# SAMA7D65D2GN8 register map
Vendor: Microchip Technology; Series: SAMA7D6; File version: 0
Registers are 32-bit, read-write, reset 0x0 unless marked. A register's access mark holds for its fields unless they carry their own. Offsets are from the block's base; [hi:lo] are bit positions; {n}, {i} and the like mark numbered series; 'fields as' and 'values as' point back to an identical list.

## ASRC — Asynchronous Sample Rate Converter
Base 0xE2808000
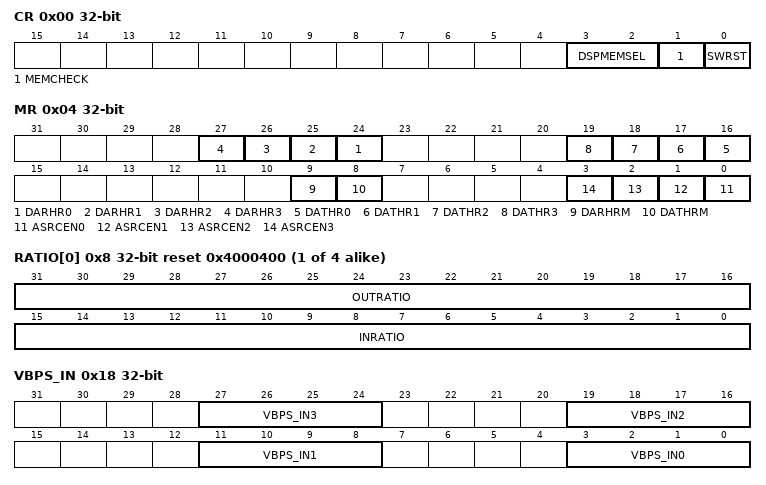
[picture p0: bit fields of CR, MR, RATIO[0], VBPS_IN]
0x00 CR wo — Control Register
  [3:2] DSPMEMSEL — DSP Memory Selection
    0=ALL_DSP_MEM (Memories of all DSPs are checked when MEMCHECK=1. When the flag ASRC_ESR.SRAMS=1, one error has been detected in one of the memories. To determine which DSP is affected, the memory check procedure must be restarted with DSPMEMSEL > 0. Note: When using only DSP0 or DSP1 or DSP3, it is possible to start the check procedure only for the selected DSP. The check of DSP2 memories requires several steps.); 1=DSP0_MEM (Only memories of DSP0 are checked when MEMCHECK=1. When the flag ASRC_ESR.SRAMS=1, one error has been detected in one of the memories associated to DSP0. The errors that may be located in other DSP memories does not impact the report on ASRC_ESR.SRAMS=1.); 2=DSP1_MEM (Only memories of DSP1 are checked when MEMCHECK=1. When the flag ASRC_ESR.SRAMS=1, one error has been detected in one of the memories associated to DSP1. The errors that may be located in other DSP memories does not impact the report on ASRC_ESR.SRAMS=1.); 3=DSP3_MEM (Only memories of DSP3 are checked when MEMCHECK=1. When the flag ASRC_ESR.SRAMS=1, one error has been detected in one of the memories associated to DSP3. The errors that may be located in other DSP memories does not impact the report on ASRC_ESR.SRAMS=1.)
  [1] MEMCHECK — Embedded Memory Check
    0=No effect; 1=Starts a memory check when all DSPs are disabled (ASRC_MR.ASRCENx=0). The end of the verification period is provided in ASRC_ISRx.EOMCP and the status is available in ASRC_ESR.ROMS/SRAMS at the end of the verification period. Clears the ASRC_ESR.ROMS/SRAMS flags.
  [0] SWRST — Software Reset
    0=No effect; 1=Resets the ASRC
0x04 MR — Mode Register
  [n+24] DARHR{n} (n=0..3) — Direct Access Receive Holding Register Destination
    0=DMA (The Receive Holding register is read by software or DMA. If DARHRM=1, the Receive Holding register is directly driving an audio peripheral. The Receive Holding register x loads the audio peripheral selected by ASRC_DAPSELR.OUT_CHx.); 1=DIRECT_ACCESS (The Receive Holding register is directly driving an audio peripheral. The Receive Holding register x loads the audio peripheral selected by ASRC_DAPSELR.OUT_CHx.)
  [n+16] DATHR{n} (n=0..3) — Direct Access Transmit Holding Register Source
    0=DMA (The Transmit Holding register is loaded by software or DMA. If DATHRM=1, the Transmit Holding register is directly loaded by an audio peripheral. The audio peripheral loading the Transmit Holding Register is selected by configuring ASRC_DAPSELR.IN_CHx.); 1=DIRECT_ACCESS (The Transmit Holding register is directly loaded by an audio peripheral. The audio peripheral loading the Transmit Holding Register is selected by configuring ASRC_DAPSELR.IN_CHx.)
  [9] DARHRM — Direct Access Receive Holding Registers Mode
    0=PER_RHR (The access mode for each receive channel (ASRC_RHRx) is defined by the bits DARHRx.); 1=ALL_RHR (All receive channels are directly driving audio peripherals. The DARHRx bits have no effect.)
  [8] DATHRM — Direct Access Transmit Holding Registers Mode
    0=PER_THR (The access mode for each transmit channel (ASRC_THRx) is defined by the bits DATHRx.); 1=ALL_THR (All transmit channels are directly loaded by audio peripherals. The DATHRx bits have no effect.)
  [n] ASRCEN{n} (n=0..3) — ASRC Stereo Channel {n} Enable
    0=DISABLE (DSPx is disabled.); 1=ENABLE (DSPx is enabled.)
{0x8+4i} RATIO[{i}] (i=0..3) reset 0x4000400 — Ratio Register of Stereo Channel x
  [31:16] OUTRATIO — Output Internal Sampling Rate Ratio
  [15:0] INRATIO — Input Internal Sampling Rate Ratio
0x18 VBPS_IN — Valid Bit Per Sample In Register
  [all] fields
    0=8_BIT (The 8 LSB of THR registers are left aligned on 24-bit data entered to the DSP. The bits [15:8] of the 24-bit data are driven by the 8 LSB of THR registers to increase the dynamic range of the data sent to DSP. The bits [7:0] are driven by 0s.); 1=16_BIT (The 16 LSB of THR registers are left aligned on 24-bit data entered to the DSP. The bits [7:0] of the 24-bit data are driven by the bits [15:8] of the THR registers to increase the dynamic range of the data sent to DSP.); 2=20_BIT (The 20 LSB of THR registers are left aligned on 24-bit data entered to the DSP. The bits [3:0] of the 24-bit data are driven by the bits [19:16] of the THR registers to increase the dynamic range of the data sent to DSP.); 3=24_BIT (The 24 LSB of THR registers are entered to the DSP.); 4=32_BIT (The 24 MSB of THR registers are entered to the DSP.); 5=10_BIT (The 10 LSB of THR registers are left aligned on 24-bit data entered to the DSP. The bits [13:4] of the 24-bit data are driven by the 10 LSB of THR registers to increase the dynamic range of the data sent to DSP. The bits [3:0] are driven by 0s.); 6=12_BIT (The 12 LSB of THR registers are left aligned on 24-bit data entered to the DSP. The bits [11:0] of the 24-bit data are driven by the bits [11:0] of the THR registers to increase the dynamic range of the data sent to DSP.); 7=14_BIT (The 14 LSB of THR registers are left aligned on 24-bit data entered to the DSP. The bits [9:0] of the 24-bit data are driven by the bits [13:4] of the THR registers to increase the dynamic range of the data sent to DSP.); 8=18_BIT (The 18 LSB of THR registers are left aligned on 24-bit data entered to the DSP. The bits [5:0] of the 24-bit data are driven by the bits [17:12] of the THR registers to increase the dynamic range of the data sent to DSP.)
  [8n+3:8n] VBPS_IN{n} (n=0..3) — Valid Bit Per Sample In of DSP {n}
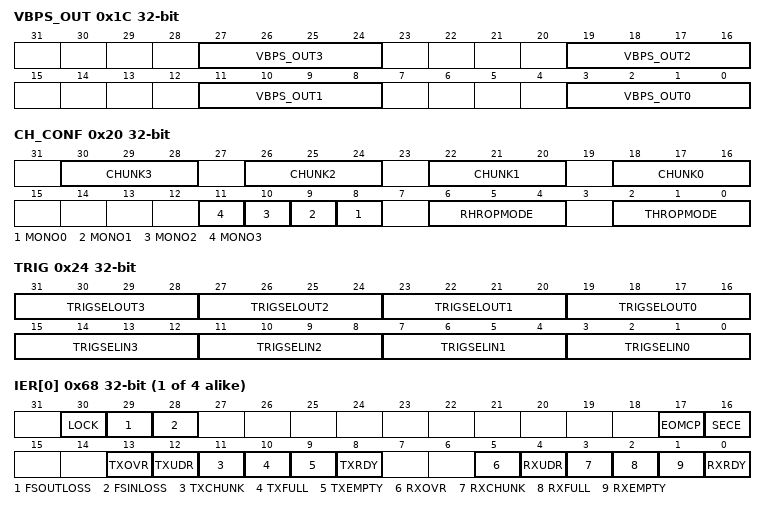
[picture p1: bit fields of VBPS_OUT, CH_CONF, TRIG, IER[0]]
0x1C VBPS_OUT — Valid Bit Per Sample Out Register
  [all] fields
    0=8_BIT (The 8 MSB of the 24-bit read from the DSP output are right-aligned on RHR.); 1=16_BIT (The 16 MSB of the 24-bit read from the DSP output are right-aligned on RHR.); 2=20_BIT (The 20 MSB of the 24-bit read from the DSP output are right-aligned on RHR.); 3=24_BIT (The 24 LSB of RHR registers are read from the 24-bit DSP output.); 4=32_BIT (The 24 MSB of RHR registers are the 24-bit output of the DSP. The 8 LSB of the RHR are driven by bits [22:15] of the DSP output.); 5=10_BIT (The 10 MSB of the 24-bit read from the DSP output are right-aligned on RHR.); 6=12_BIT (The 12 MSB of the 24-bit read from the DSP output are right-aligned on RHR.); 7=14_BIT (The 14 MSB of the 24-bit read from the DSP output are right-aligned on RHR.); 8=18_BIT (The 18 MSB of the 24-bit read from the DSP output are right-aligned on RHR.)
  [8n+3:8n] VBPS_OUT{n} (n=0..3) — Valid Bit Per Sample Out of DSP {n}
0x20 CH_CONF — Channel Configuration Register
  [4n+18:4n+16] CHUNK{n} (n=0..3) — DMA DSP {n} CHUNK Size
    0=1_DATA (The DMA chunk size must be configured to transfer 1 data for each rising edge of the trigger event.); 1=2_DATA (The DMA chunk size must be configured to transfer 2 data for each rising edge of the trigger event.); 2=4_DATA (The DMA chunk size must be configured to transfer 4 data for each rising edge of the trigger event.); 3=8_DATA (The DMA chunk size must be configured to transfer 8 data for each rising edge of the trigger event.); 4=16_DATA (The DMA chunk size must be configured to transfer 16 data for each rising edge of the trigger event.)
  [n+8] MONO{n} (n=0..3) — DSP {n} Mono Operating Mode
    0=DISABLED (DSP operates in Stereo mode.); 1=ENABLED (DSP operates in Mono mode.)
  [6:4] RHROPMODE — Receive Holding Registers Operating Mode
    0=RHRX_UPTO_2CH (The ASRC_RHRx can receive up to 2 audio streams (e.g. 1 stereo channel for each ASRC_RHR). Each ASRC_RHRx is routed on each Stereo DSP x.); 1=RHR0_UPTO_4CH (The ASRC_RHR0 can receive up to 4 audio streams (e.g. up to 2 stereo channels on ASRC_RHR0). The ARSC_RHR1 can receive up to 2 audio streams (e.g. 1 stereo channel on ASRC_RHR1). The ARSC_RHR2 can receive up to 2 audio streams (e.g. 1 stereo channel on ASRC_RHR2). ASRC_RHR3 must not be used.); 2=RHR01_UPTO_4CH (The ASRC_RHR0 can receive up to 4 audio streams (e.g. up to 2 stereo channels on ASRC_RHR0). The ASRC_RHR1 can receive up to 4 audio streams (e.g. up to 2 stereo channels on ASRC_RHR1). ASRC_RHR2 and ASRC_RHR3 must not be used.); 3=RHR0_UPTO_6CH (The ASRC_RHR0 can receive up to 6 audio streams (e.g. up to 3 stereo channels on ASRC_RHR0). The ARSC_RHR1 can receive up to 2 audio streams (e.g. 1 stereo channel on ASRC_RHR1) ASRC_RHR2 and ASRC_RHR3 must not be used.); 4=RHR0_UPTO_8CH (The ASRC_RHR0 can receive up to 8 audio streams (e.g. up to 4 stereo channels on ASRC_RHR0). ASRC_RHR1,ASRC_RHR2 and ASRC_RHR3 must not be used.)
  [2:0] THROPMODE — Transmit Holding Registers Operating Mode
    0=THRX_UPTO_2CH (The ASRC_THRx can receive up to 2 audio streams (e.g. 1 stereo channel for each ASRC_THR). Each ASRC_THRx is routed on each Stereo DSP x.); 1=THR0_UPTO_4CH (The ASRC_THR0 can receive up to 4 audio streams (e.g. up to 2 stereo channels on ASRC_THR0). The ARSC_THR1 can receive up to 2 audio streams (e.g. 1 stereo channel on ASRC_THR1). The ARSC_THR2 can receive up to 2 audio streams (e.g. 1 stereo channel on ASRC_THR2). ASRC_THR3 must not be used.); 2=THR01_UPTO_4CH (The ASRC_THR0 can receive up to 4 audio streams (e.g. up to 2 stereo channels on ASRC_THR0). The ASRC_THR1 can receive up to 4 audio streams (e.g. up to 2 stereo channels on ASRC_THR1). ASRC_THR2 and ASRC_THR3 must not be used.); 3=THR0_UPTO_6CH (The ASRC_THR0 can receive up to 6 audio streams (e.g. up to 3 stereo channels on ASRC_THR0). The ARSC_THR1 can receive up to 2 audio streams (e.g. 1 stereo channel on ASRC_THR1) ASRC_THR2 and ASRC_THR3 must not be used.); 4=THR0_UPTO_8CH (The ASRC_THR0 can receive up to 8 audio streams (e.g. up to 4 stereo channels on ASRC_THR0). ASRC_THR1,ASRC_THR2 and ASRC_RHR3 must not be used.)
0x24 TRIG — Trigger Selection Register
  [all] fields
    0=GCLKDIV (Internal trigger event, a configurable division of GCLK (see ASRC_RATIOx for divider).); 1=I2SMCC0 (Trigger event from audio peripheral.); 2=I2SMCC1 (Trigger event from audio peripheral.); 3=PDMC0 (Trigger event from audio peripheral.); 4=PDMC1 (Trigger event from audio peripheral.); 5=SSC0RX (Trigger event from audio peripheral.); 6=SSC0TX (Trigger event from audio peripheral.); 7=SSC1RX (Trigger event from audio peripheral.); 8=SSC1TX (Trigger event from audio peripheral.); 9=SPDIFTX (Trigger event from audio peripheral.); 10=SPDIFRX (Trigger event from audio peripheral.)
  [4n+19:4n+16] TRIGSELOUT{n} (n=0..3) — Output Trigger Source Selection of DSP {n}
  [4n+3:4n] TRIGSELIN{n} (n=0..3) — Input Trigger Source Selection of DSP {n}
{0x28+4i} RHR[{i}] (i=0..3) ro — Receive Holding Register x
  [31:0] DATA — Converted Data
{0x48+4i} THR[{i}] (i=0..3) wo — Transmit Holding Register x
  [31:0] DATA — Data to Convert
{0x68+4i} IER[{i}] (i=0..3) wo — Interrupt Enable Register x
  [30] LOCK — DPLL locked Interrupt Enable
  [29] FSOUTLOSS — Output Sampling Frequency Loss Interrupt Enable
  [28] FSINLOSS — Input Sampling Frequency Loss Interrupt Enable
  [17] EOMCP — End of Memory Check Period Interrupt Enable
  [16] SECE — Security/Safety Report Interrupt Enable
  [13] TXOVR — Transmit Over Flow Interrupt Enable
  [12] TXUDR — Transmit Under Flow Interrupt Enable
  [11] TXCHUNK — Transmit FIFO Chunk Interrupt Enable
  [10] TXFULL — Transmit FIFO Full Interrupt Enable
  [9] TXEMPTY — Transmit FIFO Empty Interrupt Enable
  [8] TXRDY — Transmit Ready Interrupt Enable
  [5] RXOVR — Receive Over Flow Interrupt Enable
  [4] RXUDR — Receive Under Flow Interrupt Enable
  [3] RXCHUNK — Receive FIFO Chunk Interrupt Enable
  [2] RXFULL — Receive FIFO Full Interrupt Enable
  [1] RXEMPTY — Receive FIFO Empty Interrupt Enable
  [0] RXRDY — Receive Ready Interrupt Enable
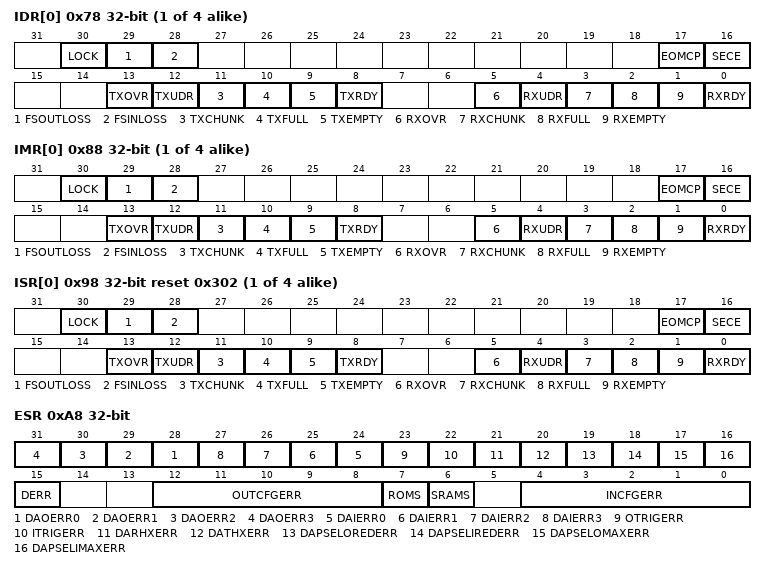
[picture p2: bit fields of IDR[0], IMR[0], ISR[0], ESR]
{0x78+4i} IDR[{i}] (i=0..3) wo — Interrupt Disable Register x
  [30] LOCK — DPLL locked Interrupt Disable
  [29] FSOUTLOSS — Output Sampling Frequency Loss Interrupt Disable
  [28] FSINLOSS — Input Sampling Frequency Loss Interrupt Disable
  [17] EOMCP — End of Memory Check Period Interrupt Disable
  [16] SECE — Security/Safety Report Interrupt Disable
  [13] TXOVR — Transmit Over Flow Interrupt Disable
  [12] TXUDR — Transmit Under Flow Interrupt Disable
  [11] TXCHUNK — Transmit FIFO Chunk Interrupt Disable
  [10] TXFULL — Transmit FIFO Full Interrupt Disable
  [9] TXEMPTY — Transmit FIFO Empty Interrupt Disable
  [8] TXRDY — Transmit Ready Interrupt Disable
  [5] RXOVR — Receive Over Flow Interrupt Disable
  [4] RXUDR — Receive Under Flow Interrupt Disable
  [3] RXCHUNK — Receive FIFO Chunk Interrupt Disable
  [2] RXFULL — Receive FIFO Full Interrupt Disable
  [1] RXEMPTY — Receive FIFO Empty Interrupt Disable
  [0] RXRDY — Receive Ready Interrupt Disable
{0x88+4i} IMR[{i}] (i=0..3) ro — Interrupt Mask Register x
  [30] LOCK — DPLL locked Interrupt Mask
  [29] FSOUTLOSS — Output Sampling Frequency Loss Interrupt Mask
  [28] FSINLOSS — Input Sampling Frequency Loss Interrupt Mask
  [17] EOMCP — End of Memory Check Period Interrupt Mask
  [16] SECE — Security/Safety Report Interrupt Mask
  [13] TXOVR — Transmit Over Flow Interrupt Mask
  [12] TXUDR — Transmit Under Flow Interrupt Mask
  [11] TXCHUNK — Transmit FIFO Chunk Interrupt Mask
  [10] TXFULL — Transmit FIFO Full Interrupt Mask
  [9] TXEMPTY — Transmit FIFO Empty Interrupt Mask
  [8] TXRDY — Transmit Ready Interrupt Mask
  [5] RXOVR — Receive Over Flow Interrupt Mask
  [4] RXUDR — Receive Under Flow Interrupt Mask
  [3] RXCHUNK — Receive FIFO Chunk Interrupt Mask
  [2] RXFULL — Receive FIFO Full Interrupt Mask
  [1] RXEMPTY — Receive FIFO Empty Interrupt Mask
  [0] RXRDY — Receive Ready Interrupt Mask
{0x98+4i} ISR[{i}] (i=0..3) ro reset 0x302 — Interrupt Status Register x
  [30] LOCK — DPLL Locked Interrupt Status (cleared by writing ASRC_MR.ASRCENx=0)
  [29] FSOUTLOSS — Output Sampling Frequency Loss Interrupt Status (cleared on read)
  [28] FSINLOSS — Input Sampling Frequency Loss Interrupt Status (cleared on read)
  [17] EOMCP — End of Memory Check Period Interrupt Status (cleared on read)
  [16] SECE — Security and/or Safety Event Interrupt Status (cleared on read)
    0=No security or safety event has occurred since the last read of ASRC_ISR register; 1=One or more safety or security events has occurred since the last read of ASRC_ISR. For details on the event, refer to ASRC_WPSR and ASRC_ESR direct access related error reports.
  [13] TXOVR — Transmit Over Flow Interrupt Status (cleared on read)
  [12] TXUDR — Transmit Under Flow Interrupt Status (cleared on read)
  [11] TXCHUNK — Transmit FIFO Chunk Interrupt Status (cleared automatically when the input FIFO has fewer samples than configured in ASRC_CH_CONF.CHUNKx)
  [10] TXFULL — Transmit FIFO Full Interrupt Status (cleared automatically when ASRC starts converting data)
  [9] TXEMPTY — Transmit FIFO Empty Interrupt Status (cleared when writing in ASRC_THRx)
  [8] TXRDY — Transmit Ready Interrupt Status (cleared automatically when input FIFO is full)
  [5] RXOVR — Receive Over Flow Interrupt Status (cleared on read)
  [4] RXUDR — Receive Under Flow Interrupt Status (cleared on read)
  [3] RXCHUNK — Receive FIFO Chunk Interrupt Status (cleared automatically when the output FIFO has fewer samples than configured in ASRC_CH_CONF.CHUNKx)
  [2] RXFULL — Receive FIFO Full Interrupt Status (cleared by reading ASRC_RHRx)
  [1] RXEMPTY — Receive FIFO Empty Interrupt Status (cleared automatically when ASRC has converted one sample)
  [0] RXRDY — Receive Ready Interrupt Status (cleared when output FIFO is empty after reading ASRC_RHRx)
0xA8 ESR ro — Error Status Register
  [n+28] DAOERR{n} (n=0..3) — Direct Access Output Transfer Error Status (cleared on read)
    0=No error detected in the direct access link with audio peripherals receiving data from ASRC; 1=A data is missing in the direct access transfer between two synchronization events (ASRC trigger events). This may be due to a bad configuration of the audio peripheral receiving the data (for example, direct access is disabled or a hardware failure).
  [n+24] DAIERR{n} (n=0..3) — Direct Access Input Transfer Error Status (cleared on read)
    0=No error detected in the direct access link with audio peripherals providing data to ASRC; 1=A data is missing in the direct access transfer between two synchronization events (ASRC trigger events). This may be due to a bad configuration of the audio peripheral transmitting the data (for example, direct access is disabled or a hardware failure) or the ASRC direct access enable for channel x is disabled whereas a synchronization event is valid on the direct access physical link (the audio peripheral transmitting the data is enabled and a data has been already transmitted). The error may also rise if the ASRC direct access is being disabled when there is data pending on the direct access link.
  [23] OTRIGERR — Output Trigger Configuration Error
    0=Validates the configuration of ASRC_TRIG.TRIGSELOUTx versus ASRC_CH_CONF.RHROPMODE; 1=The configuration of ASRC_TRIG.TRIGSELOUTx is incompatible with the configuration of ASRC_CH_CONF.RHROPMODE. The error is only reported when 1 DSP is enabled (ASRC_MR.ASRCENx differs from 0). The error is cleared when the configuration is correct.
  [22] ITRIGERR — Input Trigger Configuration Error
    0=Validates the configuration of ASRC_TRIG.TRIGSELINx versus ASRC_CH_CONF.THROPMODE; 1=The configuration of ASRC_TRIG.TRIGSELINx is incompatible with the configuration of ASRC_CH_CONF.THROPMODE. The error is only reported when 1 DSP is enabled (ASRC_MR.ASRCENx differs from 0). The error is cleared when the configuration is correct.
  [21] DARHXERR — Direct Access DARHM/DARHRx Configuration Error
    0=Validates the configuration of ASRC_MR.DARHM/DARHRx; 1=The configuration of ASRC_MR.DARHM/DARHRx is incompatible with the configuration of ASRC_CH_CONF.RHROPMODE. The error is only reported when 1 DSP is enabled (ASRC_MR.ASRCENx differs from 0). The error is cleared when the configuration is correct.
  [20] DATHXERR — Direct Access DATHM/DATHRx Configuration Error
    0=Validates the configuration of ASRC_MR.DATHM/DATHRx; 1=The configuration of ASRC_MR.DATHM/DATHRx is incompatible with the configuration of ASRC_CH_CONF.THROPMODE. The error is only reported when 1 DSP is enabled (ASRC_MR.ASRCENx differs from 0). The error is cleared when the configuration is correct.
  [19] DAPSELOREDERR — Direct Access Output Peripheral Selection Redundancy Configuration Error
    0=Validates the configuration of ASRC_DAPSELR.OUT_CHx and ASRC_MR.DARHRx; 1=The same audio peripheral is enabled to transmit data into more than one direct access channel. The ASRC_DAPSELR.OUT_CHx and ASRC_MR.DARHRx must be correctly configured to clear the error.
  [18] DAPSELIREDERR — Direct Access Input Peripheral Selection Redundant Configuration Error
    0=Validates the configuration of ASRC_DAPSELR.IN_CHx and ASRC_MR.DATHRx; 1=The same audio peripheral is enabled to receive data into more than one direct access channel. The ASRC_DAPSELR.IN_CHx and ASRC_MR.DATHRx must be correctly configured to clear the error.
  [17] DAPSELOMAXERR — Direct Access Output Peripheral Selection Configuration Error on Maximum Values
    0=None of the values in ASRC_DAPSELR.OUT_CHx fields overpass the maximum number of audio peripherals allowed to transfer data directly from the ASRC or the related direct access receive channel is disabled in ASRC_MR.DARHRx; 1=One of the values in ASRC_DAPSELR.OUT_CHx fields overpass the maximum number of audio peripherals allowed to transfer data directly from the ASRC and the related direct access receive channel is enabled in ASRC_MR.DARHRx. The error is cleared when the configuration is correct.
  [16] DAPSELIMAXERR — Direct Access Input Peripheral Selection Configuration Error on Maximum Values
    0=None of the values in ASRC_DAPSELR.IN_CHx fields overpass the maximum number of audio peripherals allowed to transfer data directly to the ASRC or the related direct access transmit channel is disabled in ASRC_MR.DATHRx; 1=One of the values in ASRC_DAPSELR.IN_CHx fields overpass the maximum number of audio peripherals allowed to transfer data directly to the ASRC and the related direct access transmit channel is enabled in ASRC_MR.DATHRx. The error is cleared when the configuration is correct.
  [15] DERR — DSP Overflow Error (cleared on read)
    0=No DSP overflow error detected; 1=The sampling frequency overpasses the value allowed by the configuration
  [12:8] OUTCFGERR — Output Configuration Error
    0=OUTCFG_OK (Correct configuration of ASRC_MR, ASRC_VBPS_OUT, ASRC_CH_CONF.); {v}=OP0_D{v-1}_CHK16_8M (Channel operating mode 0, DSP{v-1}: CHUNK{v-1}=16 or CHUNK{v-1}=8 and MONO{v-1}=1 is not supported.) (v=1..4); 5=OP1_D01_EN (Channel operating mode 1, DSP0/1: enable configuration is not correct (1 DSP is disabled)); 6=OP1_D01_M (Channel operating mode 1, DSP0/1: MONO0=1, MONO1=0 is not supported.); 7=OP1_D01_CHK16 (Channel operating mode 1, DSP0/1: CHUNK0=16 is not supported.); 8=OP1_D2_CHK16_8M (Channel operating mode 1, DSP2: CHUNK2=16 or CHUNK2=8 and MONO2=1 is not supported.); 9=OP1_D3_CHK16_8M (Channel operating mode 1, DSP3: CHUNK3=16 or CHUNK3=8 and MONO3=1 is not supported.); 10=OP2_D01_EN (Channel operating mode 2, DSP0/1: enable configuration is not correct (1 DSP is disabled)); 11=OP2_D01_M (Channel operating mode 2, DSP0/1: MONO0=1, MONO1=0 is not supported.); 12=OP2_D01_CHK16 (Channel operating mode 2, DSP0/1: CHUNK0=16 is not supported.); 13=OP2_D23_EN (Channel operating mode 2, DSP2/3: enable configuration is not correct (1 DSP is disabled)); 14=OP2_D23_M (Channel operating mode 2, DSP2/3: MONO2=1, MONO3=0 is not supported.); 15=OP2_D23_CHK16 (Channel operating mode 2, DSP2/3: CHUNK2=16 is not supported.); 16=OP3_D012_EN (Channel operating mode 3, DSP0/1/2: enable configuration is not correct (at least 1 DSP is disabled)); 17=OP3_D012_M (Channel operating mode 3, DSP0/1/2: mono configuration is not correct (e.g. MONO0=1, MONO1=0 or MONO2=0 is not supported).); 18=OP3_D012_CHK16 (Channel operating mode 3, DSP0/1/2: CHUNK0=16 is not supported.); 19=OP3_D3_CHK16_8M (Channel operating mode 3, DSP3: CHUNK3=16 or CHUNK3=8 and MONO3 is not supported.); 20=OP4_D0123_EN (Channel operating mode 4, DSP0/1/2/3: enable configuration is not correct (at least 1 DSP is disabled)); 21=OP4_D0123_M (Channel operating mode 4, DSP0/1/2/3: mono configuration is not correct (e.g. MONO0=1, MONO1=0 or MONO2=0 or MONO3=0 is not supported).)
  [7] ROMS — DSP ROM Memory Check Status
    0=No error detected in the embedded memory when the check period is completed. When testing the ability for ROMS to rise by writing ASRC_FIR.F0=1, the clear is performed by first clearing ASRC_FIR.F0 followed by an additional read of the ASRC_WPSR to clear ASRC_ISRx.SECE, then restarting a memory check period again. When a permanent memory hardware failure exists, there is no way to clear this flag.; 1=The embedded ROM memory contains a failure (check done with a CRC24, polynomial: 0x864CFB). This flag is cleared at the start of any memory check procedure.
  [6] SRAMS — DSP SRAM Memory Check Status
    0=No error detected in the embedded memory when the check period is completed. When testing the ability for SRAMS to rise by writing ASRC_FIR.F0=1, the clear is performed by first clearing ASRC_FIR.F0 followed by an additional read of the ASRC_WPSR to clear ASRC_ISRx.SECE, then restarting a memory check period again. When a permanent memory hardware failure exists for a selected channel, it is possible to clear this flag by starting the memory check for another channel where memories does not embed permanent hardware failure.; 1=One of the embedded RAM memories contains a failure. When ASRC_MR.DSPMEMSEL=0, one of the RAMs fails. ASRC_MR.DSPMEMSEL must be configured successively with values greater than 0 to determine the affected channel/DSP. This flag is cleared at the start of any memory check procedure.
  [4:0] INCFGERR — Input Configuration Error
    values as OUTCFGERR
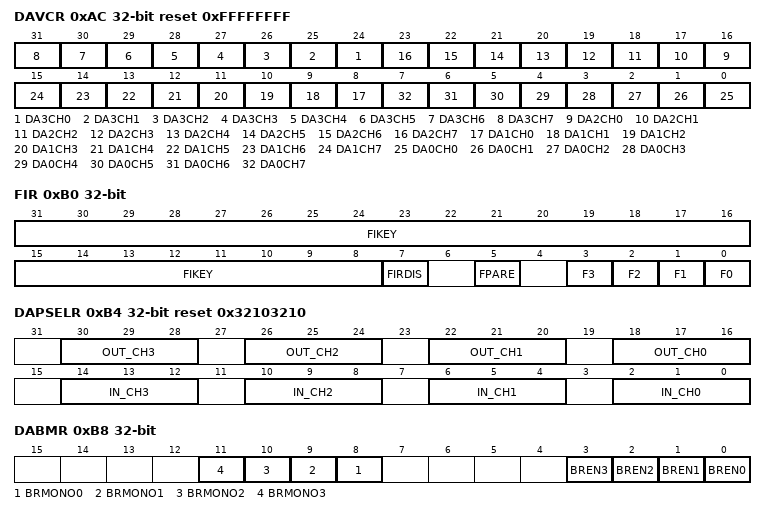
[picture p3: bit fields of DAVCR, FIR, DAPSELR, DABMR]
0xAC DAVCR reset 0xFFFFFFFF — Direct Access Valid Channels Register
  [n+24] DA3CH{n} (n=0..7) — Direct Access Input Stream 3 Channel {n} Enable
    0=DISABLE (The channel x of the direct access input stream 3 is not passed to any DSP.); 1=ENABLE (The channel x of the direct access input stream 3 is converted by a DSP.)
  [n+16] DA2CH{n} (n=0..7) — Direct Access Input Stream 2 Channel {n} Enable
    0=DISABLE (The channel x of the direct access input stream 2 is not passed to any DSP.); 1=ENABLE (The channel x of the direct access input stream 2 is converted by a DSP.)
  [n+8] DA1CH{n} (n=0..7) — Direct Access Input Stream 1 Channel {n} Enable
    0=DISABLE (The channel x of the direct access input stream 1 is not passed to any DSP.); 1=ENABLE (The channel x of the direct access input stream 1 is converted by a DSP.)
  [n] DA0CH{n} (n=0..7) — Direct Access Input Stream 0 Channel {n} Selection
    0=DISABLE (The channel x of the direct access input stream 0 is not passed to any DSP.); 1=ENABLE (The channel x of the direct access input stream 0 is converted by a DSP.)
0xB0 FIR — Fault Injection Register
  [31:8] FIKEY — Fault Injection Access Key
    0x414649=PASSWD (Writing any other value in this field aborts the write operation.)
  [7] FIRDIS — Fault Injection Register Disable
    0=NO_EFFECT; 1=ACTIVE (Disables the fault injection until the next hardware reset. The command is valid only if the ASRCC_WPSR.SEQE=0 and the other bits are cleared (F0=F1=F2=F3=FPARE=0).)
  [5] FPARE — Single Fault for ASRC Mode Register
    0=NO_EFFECT; 1=INJECT_CLEAR (Injects a single fault on the configuration register if the ASRC DSP are all disabled (for security reason), the flag ASRC_WPSR.SEQE=1 and the flag ASRC_ISRx.SECE =1. Clears the fault if it has been previously injected.)
  [3] F3 — Single Fault for ASRC Write Protection Control Enable (ASRC_WPMR.WPCREN)
    0=Clears the fault; 1=Injects a single fault on the reinforced safety for the ASRC_WPMR.WPCREN bit if 0x414649 ('AFI' in ASCII) is written in the FIKEY field at the same time. The ASRC remains in the same state, the flag ASRC_ISRx.SECE=1 and the flag ASRC_WPSR.SDEE=1.
  [2] F2 — Single Fault for ASRC Write Protection Interrupt Enable (ASRC_WPMR.WPITEN)
    0=Clears the fault; 1=Injects a single fault on the reinforced safety for the ASRC_WPMR.WPITEN bit if 0x414649 ('AFI' in ASCII) is written in the FIKEY field at the same time. The ASRC remains in the same state, the flag ASRC_ISRx.SECE=1 and the flag ASRC_WPSR.SDEE=1.
  [1] F1 — Single Fault for ASRC Write Protection Configuration Enable (ASRC_WPMR.WPEN)
    0=Clears the fault; 1=Injects a single fault on the reinforced safety for the ASRC_WPMR.WPEN bit if 0x414649 ('AFI' in ASCII) is written in the FIKEY field at the same time. The ASRC remains in the same state, the flag ASRC_ISRx.SECE=1 and the flag ASRC_WPSR.SDEE=1.
  [0] F0 — Single Fault for ASRC DSP0 Enable (ASRC_MR.ASRCEN0)
    0=Clears the fault. Writing a 0 to this bit clears ASRC_ESR.ROMS/SRAMS if the write is done before reading ASRC_WPSR and before starting a new memory check procedure.; 1=Injects a single fault on the reinforced safety for the ASRC_MR.ASRCENx bit if 0x414649 ('AFI' in ASCII) is written in the FIKEY field at the same time. The ASRC remains in the same state, the flag ASRC_ISRx.SECE=1 and the flag ASRC_WPSR.SDEE=1. When the memory check is started (ASRC_CR.MEMCHECK=1), injects also a fault in the data read from embedded memories to verify the memory checker. Thus at the end of the memory check period (ASRC_ISRx.EOMCP=1) the flag ASRC_ESR.ROMS=1 and ASRC_ESR.SRAMS=1.
0xB4 DAPSELR reset 0x32103210 — Direct Access Peripheral Select Register
  [4n+18:4n+16] OUT_CH{n} (n=0..3) — Direct Access Channel {n} Output Audio Peripheral Destination
    0=AUDIOSTREAM0 (The direct access channel x is directly driving the I2SMCC1 TX when ASRC_MR.DARHRx=1 or ASRC_MR.DARHRM=1.); 1=AUDIOSTREAM1 (The direct access channel x is directly driving the I2SMCC0 TX when ASRC_MR.DARHRx=1 or ASRC_MR.DARHRM=1.); 2=AUDIOSTREAM2 (The direct access channel x is directly driving the SPDIFTX when ASRC_MR.DARHRx=1 or ASRC_MR.DARHRM=1.); 3=AUDIOSTREAM3 (The direct access channel x is directly driving the SSC0 TX when ASRC_MR.DARHRx=1 or ASRC_MR.DARHRM=1.); 4=AUDIOSTREAM4 (The direct access channel x is directly driving the SSC1 TX when ASRC_MR.DARHRx=1 or ASRC_MR.DARHRM=1.)
  [4n+2:4n] IN_CH{n} (n=0..3) — Direct Access Channel {n} Input Audio Peripheral Source
    0=AUDIOSTREAM0 (The direct access channel x is directly driven by I2SMCC0 RX when ASRC_MR.DATHRx=1or ASRC_MR.DATHRM=1.); 1=AUDIOSTREAM1 (The direct access channel x is directly driven by I2SMCC1 RX when ASRC_MR.DATHRx=1 or ASRC_MR.DATHRM=1.); 2=AUDIOSTREAM2 (The direct access channel x is directly driven by SPDIFRX. when ASRC_MR.DATHRx=1 or ASRC_MR.DATHRM=1.); 3=AUDIOSTREAM3 (The direct access channel x is directly driven by PDMC0. when ASRC_MR.DATHRx=1 or ASRC_MR.DATHRM=1.); 4=AUDIOSTREAM4 (The direct access channel x is directly driven by PDMC1. when ASRC_MR.DATHRx=1 or ASRC_MR.DATHRM=1.); 5=AUDIOSTREAM5 (The direct access channel x is directly driven by SSC0 RX. when ASRC_MR.DATHRx=1 or ASRC_MR.DATHRM=1.); 6=AUDIOSTREAM6 (The direct access channel x is directly driven by SSC1 RX. when ASRC_MR.DATHRx=1 or ASRC_MR.DATHRM=1.)
0xB8 DABMR — Direct Access Bridge Mode Register
  [n+8] BRMONO{n} (n=0..3) — Direct Access Input/Output Bridging Mono Transfer for Channel {n}
    0=Disables mono audio transfer when the corresponding channel is configured in Bridging mode (BRENx=1); 1=Enables mono audio transfer when the corresponding channel is configured in Bridging mode (BRENx=1)
  [n] BREN{n} (n=0..3) — Direct Access Input/Output Bridging Enable for Channel {n}
    0=Disables the input/output direct bridging capability for direct channel x (data rate conversion is possible for channel x); 1=Enables the input/output direct bridging capability for direct channel x (no data rate conversion is performed on channel x ). Any input audio peripheral can drive directly an output audio peripheral. Peripherals are selected via ASRC_DAPSELR. Direct Access mode must be enabled in ASRC_MR.
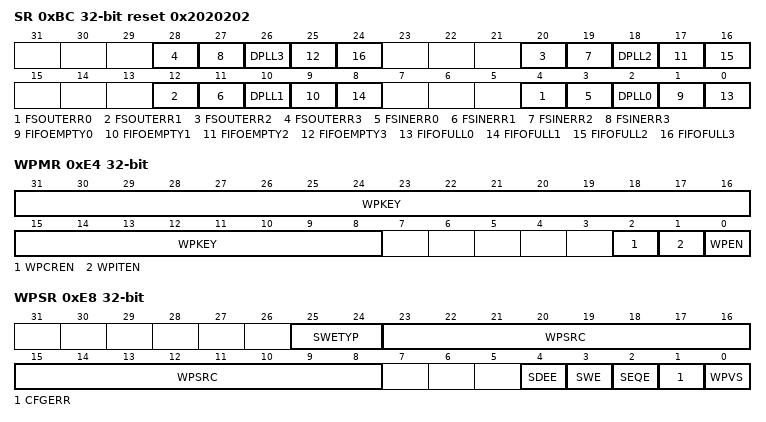
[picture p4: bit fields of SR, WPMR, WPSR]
0xBC SR ro reset 0x2020202 — Status Register
  [8n+4] FSOUTERR{n} (n=0..3) — DSPx Output Sampling Frequency Status
    0=DSPx output sampling frequency is correct; 1=DSPx output sampling frequency is abnormal (loss or deviation greater than 4 times the initial value registered when the conversion has been enabled)
  [8n+3] FSINERR{n} (n=0..3) — DSPx Input Sampling Frequency Status
    0=DSPx input sampling frequency is correct; 1=DSPx input sampling frequency is abnormal (loss or deviation greater than 4 times the initial value registered when the conversion has been enabled)
  [8n+2] DPLL{n} (n=0..3) — DSPx Digital PLL Status
    0=UNLOCKED (DSPx Digital PLL is unlocked.); 1=LOCKED (DSPx Digital PLL is locked.)
  [8n+1] FIFOEMPTY{n} (n=0..3) — DSPx FIFO Empty
    0=DSPx FIFO is not empty; 1=DSPx FIFO is empty
  [8n] FIFOFULL{n} (n=0..3) — DSPx FIFO Full
    0=DSPx FIFO is not full; 1=DSPx FIFO is full
0xE4 WPMR — Write Protection Mode Register
  [31:8] WPKEY — Write Protection Key
    0x535243=PASSWD (Writing any other value in this field aborts the write operation of the WPEN, WPITEN and WPCREN bits. Always read at 0.)
  [2] WPCREN — Write Protection Control Register Enable
    0=The write protection of control registers is disabled; 1=The write protection of control registers is enabled. Any attempt to modify the control register configuration is cancelled and leads to an error in the ASRC_WPSR register.
  [1] WPITEN — Write Protection Interrupt Enable
    0=The write protection of interrupt registers is disabled; 1=The write protection of interrupt registers is enabled. Any attempt to modify the interrupt configuration is cancelled and leads to an error in the ASRC_WPSR register.
  [0] WPEN — Write Protection Enable
    0=The write protection is disabled; 1=The write protection is enabled. All write accesses to configuration registers are canceled and generate an error in the ASRC_WPSR register
0xE8 WPSR — Write Protection Status Register
  [25:24] SWETYP — Software Error Type (cleared on read)
    0=READ_WO (A Write-only register has been read.); 1=WRITE_RO (A write access has been performed on a Read-only register.); 2=UNDEF_RW (Access to an undefined address.)
  [23:8] WPSRC — Write Protection Source (cleared on read)
  [4] SDEE — Single or Dual Event Error (cleared by reconfiguring the faulty registers or by clearing the error via ASRC_FIR)
    0=No single or dual error detected in ASRC_MR.ASRCENx, ASRC_WPMR.WPEN/WPITEN/WPCREN bits. When testing the ability for SDEE to rise by introducing a fault via ASRC_FIR, the clear is performed by first clearing the fault via ASRC_FIR, then reading ASRC_WPSR again.; 1=Single or dual error detected in ASRC_MR.ASRCENx, ASRC_WPMR.WPEN/WPITEN/WPCREN bits. If a single error event occurred, the error is filtered and has no effect on ASRC.
  [3] SWE — Software Control Error (cleared on read)
    0=No software error has occurred since the last read of ASRC_WPSR; 1=A software error has occurred since the last read of ASRC_WPSR. The field SWETYP details the type of software error; the associated incorrect software access is reported in the field WPVSRC (if WPVS=0).
  [2] SEQE — Internal Sequencer Error (cleared on read)
    0=No peripheral internal sequencer error has occurred since the last read of ASRC_WPSR; 1=A peripheral internal sequencer error has occurred since the last read of ASRC_WPSR. This flag is set under abnormal operating conditions or if the fault injection ASRC_FIR.FPARE is performed (only available if ASRC DSPs are all disabled). All ASRC configuration registers are monitored with a parity check for each register.
  [1] CFGERR — SRC Configuration Error (cleared by correcting the faulty configuration)
    0=No configuration error is reported in ASRC_ESR since the last read of ASRC_WPSR; 1=A configuration error has been detected and reported in ASRC_ESR, since the last read of ASRC_WPSR
  [0] WPVS — Write Protection Violation Status (cleared on read)
    0=No write protection violation has occurred since the last read of ASRC_WPSR; 1=A write protection violation has occurred since the last read of ASRC_WPSR. If this violation is an unauthorized attempt to write a protected register, the associated violation is reported in field WPSRC.
